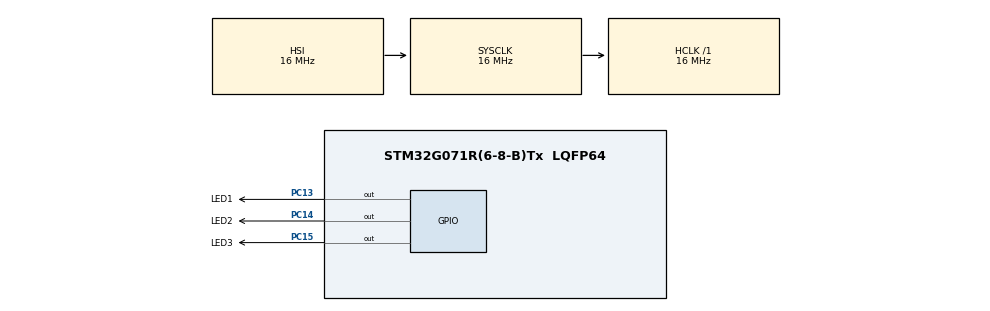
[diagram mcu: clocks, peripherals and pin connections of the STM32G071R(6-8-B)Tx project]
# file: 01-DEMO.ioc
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Mcu.Family=STM32G0
Mcu.Name=STM32G071R(6-8-B)Tx
Mcu.Package=LQFP64
PA13.Mode=Serial_Wire
PA13.Signal=SYS_SWDIO
PA14-BOOT0.Mode=Serial_Wire
PA14-BOOT0.Signal=SYS_SWCLK
PC13.GPIO_Label=LED1
PC13.Signal=GPIO_Output
PC14-OSC32_IN\ (PC14).GPIO_Label=LED2
PC14-OSC32_IN\ (PC14).Signal=GPIO_Output
PC15-OSC32_OUT\ (PC15).GPIO_Label=LED3
PC15-OSC32_OUT\ (PC15).Signal=GPIO_Output
PF0-OSC_IN\ (PF0).Mode=HSE-External-Oscillator
PF0-OSC_IN\ (PF0).Signal=RCC_OSC_IN
PF1-OSC_OUT\ (PF1).Mode=HSE-External-Oscillator
PF1-OSC_OUT\ (PF1).Signal=RCC_OSC_OUT
ProjectManager.HeapSize=0x200
ProjectManager.StackSize=0x400
ProjectManager.TargetToolchain=CMake
RCC.AHBFreq_Value=16000000
RCC.CortexFreq_Value=16000000
RCC.EXTERNAL_CLOCK_VALUE=48000
RCC.HCLKFreq_Value=16000000
RCC.HSE_VALUE=8000000
RCC.HSI_VALUE=16000000
RCC.LSE_VALUE=32768
RCC.SYSCLKFreq_VALUE=16000000
RCC.VCOOutputFreq_Value=128000000
board=custom

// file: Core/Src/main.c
/* USER CODE BEGIN Header */
/**
  ******************************************************************************
  * @file           : main.c
  * @brief          : Main program body
  ******************************************************************************
  * @attention
  *
  * Copyright (c) 2025 STMicroelectronics.
  * All rights reserved.
  *
  * This software is licensed under terms that can be found in the LICENSE file
  * in the root directory of this software component.
  * If no LICENSE file comes with this software, it is provided AS-IS.
  *
  ******************************************************************************
  */
/* USER CODE END Header */
#include "main.h"
#include "gpio.h"

void SystemClock_Config(void);

int main(void)
{

  /* MCU Configuration--------------------------------------------------------*/

  /* Reset of all peripherals, Initializes the Flash interface and the Systick. */
  HAL_Init();

  /* Configure the system clock */
  SystemClock_Config();

  /* Initialize all configured peripherals */
  MX_GPIO_Init();

  /* Infinite loop */
  /* USER CODE BEGIN WHILE */
  void user_code();
  while (1)
  {
    /* USER CODE END WHILE */
    user_code();
  }
}

void SystemClock_Config(void)
{
  RCC_OscInitTypeDef RCC_OscInitStruct = {0};
  RCC_ClkInitTypeDef RCC_ClkInitStruct = {0};

  /** Configure the main internal regulator output voltage
  */
  HAL_PWREx_ControlVoltageScaling(PWR_REGULATOR_VOLTAGE_SCALE1);

  /** Initializes the RCC Oscillators according to the specified parameters
  * in the RCC_OscInitTypeDef structure.
  */
  RCC_OscInitStruct.OscillatorType = RCC_OSCILLATORTYPE_HSI;
  RCC_OscInitStruct.HSIState = RCC_HSI_ON;
  RCC_OscInitStruct.HSIDiv = RCC_HSI_DIV1;
  RCC_OscInitStruct.HSICalibrationValue = RCC_HSICALIBRATION_DEFAULT;
  RCC_OscInitStruct.PLL.PLLState = RCC_PLL_NONE;
  if (HAL_RCC_OscConfig(&RCC_OscInitStruct) != HAL_OK)
  {
    Error_Handler();
  }

  /** Initializes the CPU, AHB and APB buses clocks
  */
  RCC_ClkInitStruct.ClockType = RCC_CLOCKTYPE_HCLK|RCC_CLOCKTYPE_SYSCLK
                              |RCC_CLOCKTYPE_PCLK1;
  RCC_ClkInitStruct.SYSCLKSource = RCC_SYSCLKSOURCE_HSI;
  RCC_ClkInitStruct.AHBCLKDivider = RCC_SYSCLK_DIV1;
  RCC_ClkInitStruct.APB1CLKDivider = RCC_HCLK_DIV1;

  if (HAL_RCC_ClockConfig(&RCC_ClkInitStruct, FLASH_LATENCY_0) != HAL_OK)
  {
    Error_Handler();
  }
}

void Error_Handler(void)
{
  __disable_irq();
  while (1)
  {
  }
}
